VERSION ""

NS_ :

BS_:

BU_: XXX

BO_ 85 CID_TVHRJD: 8 XXX
 SG_ sig_fqiilo : 40|1@1+ (1,0) [0|1] "" XXX
 SG_ sig_sexmym : 56|8@1+ (1,0) [0|255] "" XXX

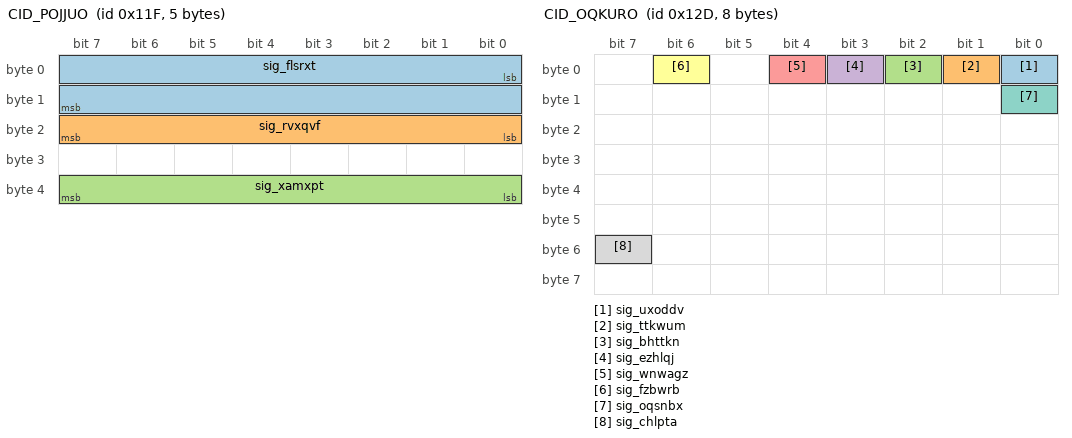
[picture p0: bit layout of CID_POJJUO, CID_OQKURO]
BO_ 287 CID_POJJUO: 5 XXX
 SG_ sig_flsrxt : 0|16@1- (0.1,0) [-450|450] "" XXX
 SG_ sig_rvxqvf : 16|8@1+ (4,0) [0|1020] "" XXX
 SG_ sig_xamxpt : 32|8@1+ (1,0) [0|255] "" XXX

BO_ 289 CID_ADYSGF: 8 XXX
 SG_ sig_qlnbtm : 0|12@1+ (1,0) [0|255] "" XXX

BO_ 301 CID_OQKURO: 8 XXX
 SG_ sig_uxoddv : 0|1@0+ (1,0) [0|1] "" XXX
 SG_ sig_ttkwum : 1|1@0+ (1,0) [0|1] "" XXX
 SG_ sig_bhttkn : 2|1@0+ (1,0) [0|1] "" XXX
 SG_ sig_ezhlqj : 3|1@0+ (1,0) [0|1] "" XXX
 SG_ sig_wnwagz : 4|1@0+ (1,0) [0|1] "" XXX
 SG_ sig_fzbwrb : 6|1@0+ (1,0) [0|1] "" XXX
 SG_ sig_oqsnbx : 8|1@0+ (1,0) [0|1] "" XXX
 SG_ sig_chlpta : 55|1@0+ (1,0) [0|1] "" XXX

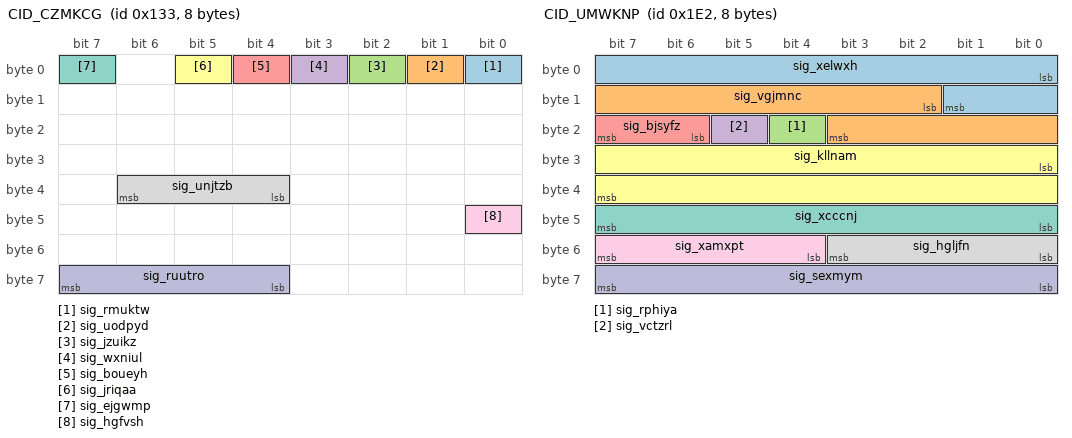
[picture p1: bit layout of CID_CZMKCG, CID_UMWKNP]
BO_ 307 CID_CZMKCG: 8 XXX
 SG_ sig_rmuktw : 0|1@0+ (1,0) [0|1] "" XXX
 SG_ sig_uodpyd : 1|1@1+ (1,0) [0|1] "" XXX
 SG_ sig_jzuikz : 2|1@1+ (1,0) [0|1] "" XXX
 SG_ sig_wxniul : 3|1@1+ (1,0) [0|1] "" XXX
 SG_ sig_boueyh : 4|1@0+ (1,0) [0|1] "" XXX
 SG_ sig_jriqaa : 5|1@0+ (1,0) [0|1] "" XXX
 SG_ sig_ejgwmp : 7|1@0+ (1,0) [0|1] "" XXX
 SG_ sig_unjtzb : 36|3@1+ (1,0) [0|7] "" XXX
 SG_ sig_hgfvsh : 40|1@0+ (1,0) [0|1] "" XXX
 SG_ sig_ruutro : 63|4@0+ (1,0) [0|15] "" XXX

BO_ 482 CID_UMWKNP: 8 XXX
 SG_ sig_xelwxh : 0|10@1- (0.01,0) [0|5] "" XXX
 SG_ sig_vgjmnc : 10|10@1- (0.01,0) [-5|0] "" XXX
 SG_ sig_rphiya : 20|1@0+ (1,0) [0|1] "" XXX
 SG_ sig_vctzrl : 21|1@0+ (1,0) [0|1] "" XXX
 SG_ sig_bjsyfz : 22|2@1+ (1,0) [0|1] "" XXX
 SG_ sig_kllnam : 24|16@1- (0.1,0) [-780|779.9] "" XXX
 SG_ sig_xcccnj : 47|8@0+ (1,0) [0|255] "" XXX
 SG_ sig_hgljfn : 48|4@1+ (1,0) [0|15] "" XXX
 SG_ sig_xamxpt : 52|4@1+ (1,0) [0|15] "" XXX
 SG_ sig_sexmym : 56|8@1+ (1,0) [0|255] "" XXX

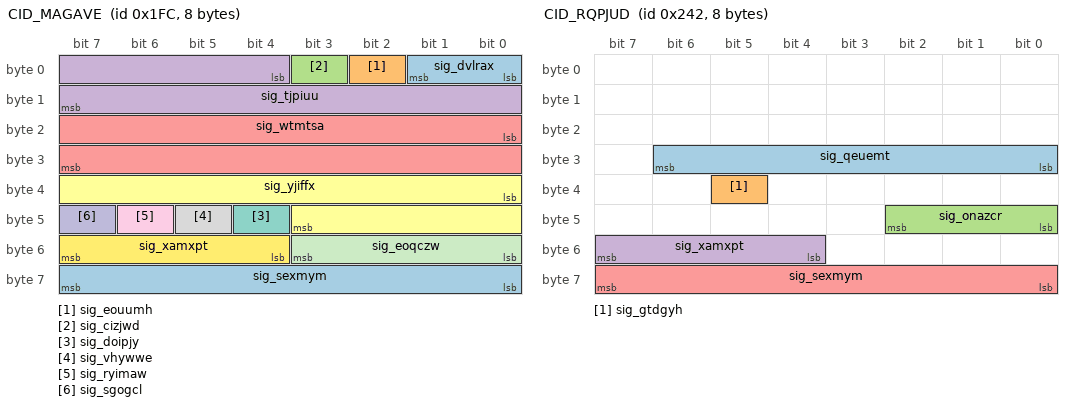
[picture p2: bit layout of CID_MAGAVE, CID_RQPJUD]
BO_ 508 CID_MAGAVE: 8 XXX
 SG_ sig_dvlrax : 0|2@1+ (1,0) [0|1] "" XXX
 SG_ sig_eouumh : 2|1@1+ (1,0) [0|1] "" XXX
 SG_ sig_cizjwd : 3|1@0+ (1,0) [0|1] "" XXX
 SG_ sig_tjpiuu : 4|12@1- (1,0) [-2048|2047] "" XXX
 SG_ sig_wtmtsa : 16|16@1- (0.1,0) [-780|779.9] "Deg" XXX
 SG_ sig_yjiffx : 32|12@1- (0.01,0) [0|63] "" XXX
 SG_ sig_doipjy : 44|1@0+ (1,0) [0|1] "" XXX
 SG_ sig_vhywwe : 45|1@1+ (1,0) [0|255] "" XXX
 SG_ sig_ryimaw : 46|1@1+ (1,0) [0|1] "" XXX
 SG_ sig_sgogcl : 47|1@0+ (1,0) [0|3] "" XXX
 SG_ sig_eoqczw : 48|4@1+ (1,0) [0|15] "" XXX
 SG_ sig_xamxpt : 52|4@1+ (1,0) [0|15] "" XXX
 SG_ sig_sexmym : 56|8@1+ (1,0) [0|255] "" XXX

BO_ 578 CID_RQPJUD: 8 XXX
 SG_ sig_qeuemt : 30|7@0+ (1,0) [0|127] "" XXX
 SG_ sig_gtdgyh : 37|1@0+ (1,0) [0|1] "" XXX
 SG_ sig_onazcr : 40|3@1+ (1,0) [0|7] "" XXX
 SG_ sig_xamxpt : 55|4@0+ (1,0) [0|15] "" XXX
 SG_ sig_sexmym : 56|8@1+ (1,0) [0|255] "" XXX

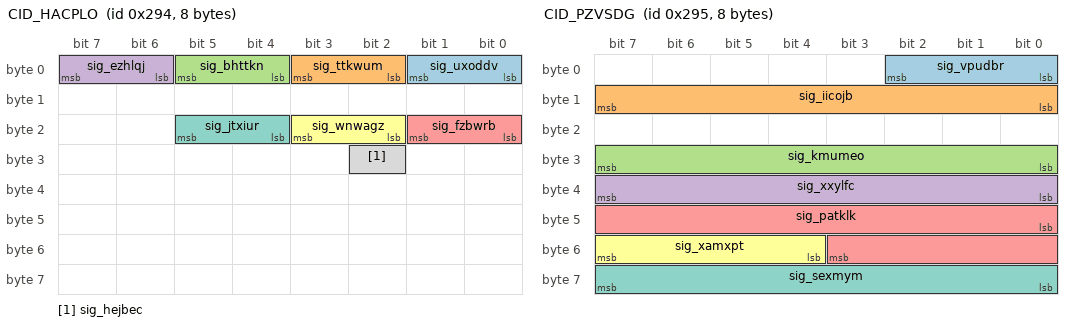
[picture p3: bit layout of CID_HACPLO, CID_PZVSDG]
BO_ 660 CID_HACPLO: 8 XXX
 SG_ sig_uxoddv : 1|2@0+ (1,0) [0|3] "" XXX
 SG_ sig_ttkwum : 3|2@0+ (1,0) [0|3] "" XXX
 SG_ sig_bhttkn : 5|2@0+ (1,0) [0|3] "" XXX
 SG_ sig_ezhlqj : 7|2@0+ (1,0) [0|3] "" XXX
 SG_ sig_fzbwrb : 17|2@0+ (1,0) [0|3] "" XXX
 SG_ sig_wnwagz : 19|2@0+ (1,0) [0|3] "" XXX
 SG_ sig_jtxiur : 21|2@0+ (1,0) [0|3] "" XXX
 SG_ sig_hejbec : 26|1@0+ (1,0) [0|1] "" XXX

BO_ 661 CID_PZVSDG: 8 XXX
 SG_ sig_vpudbr : 2|3@0+ (1,0) [0|7] "" XXX
 SG_ sig_iicojb : 15|8@0+ (1,0) [0|255] "" XXX
 SG_ sig_kmumeo : 31|8@0+ (1,0) [0|255] "" XXX
 SG_ sig_xxylfc : 32|8@1+ (1,0) [0|255] "" XXX
 SG_ sig_patklk : 40|12@1+ (1,0) [0|255] "" XXX
 SG_ sig_xamxpt : 52|4@1+ (1,0) [0|15] "" XXX
 SG_ sig_sexmym : 63|8@0+ (1,0) [0|255] "" XXX

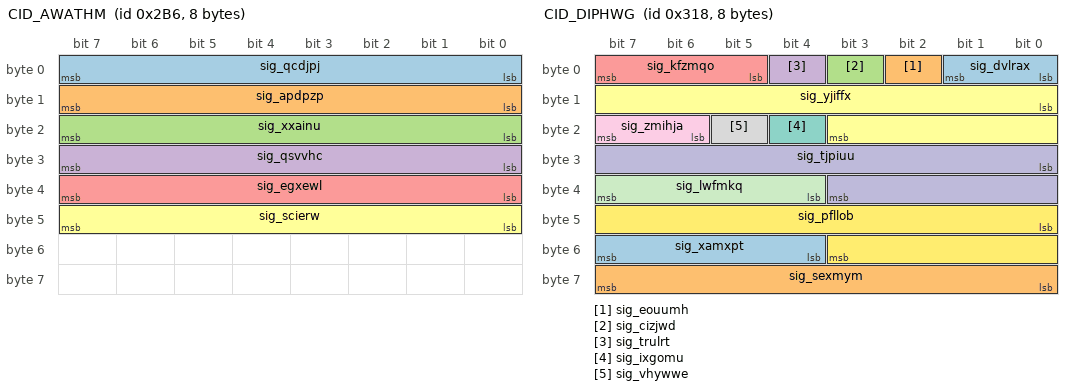
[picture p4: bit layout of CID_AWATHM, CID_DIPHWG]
BO_ 694 CID_AWATHM: 8 XXX
 SG_ sig_qcdjpj : 7|8@0+ (1,0) [0|255] "" XXX
 SG_ sig_apdpzp : 15|8@0+ (1,0) [0|255] "" XXX
 SG_ sig_xxainu : 23|8@0+ (1,0) [0|255] "" XXX
 SG_ sig_qsvvhc : 31|8@0+ (1,0) [0|255] "" XXX
 SG_ sig_egxewl : 39|8@0+ (1,0) [0|255] "" XXX
 SG_ sig_scierw : 47|8@0+ (1,0) [0|255] "" XXX

BO_ 790 CID_NQWMXH: 8 XXX
 SG_ sig_nwiqqp : 3|4@0+ (1,0) [0|1] "" XXX
 SG_ sig_dndjfb : 4|2@1+ (1,0) [0|3] "" XXX
 SG_ sig_wgoupi : 6|2@1+ (1,0) [0|3] "" XXX
 SG_ sig_kgfmkr : 8|2@1+ (1,0) [0|3] "" XXX
 SG_ sig_uyyupf : 10|1@1+ (1,0) [0|1] "" XXX
 SG_ sig_xxpklw : 11|4@1+ (1,0) [0|1] "" XXX
 SG_ sig_njyilw : 15|1@0+ (1,0) [0|1] "" XXX
 SG_ sig_kllnam : 16|11@1- (1,0) [-1024|1023] "" XXX
 SG_ sig_rphiya : 27|1@1+ (1,0) [0|1] "" XXX
 SG_ sig_vctzrl : 28|1@1+ (1,0) [0|3] "" XXX
 SG_ sig_sdakms : 29|1@0+ (1,0) [0|1] "" XXX
 SG_ sig_wikmzh : 30|1@0+ (1,0) [0|1] "" XXX
 SG_ sig_yrdwur : 31|1@0+ (1,0) [0|1] "" XXX
 SG_ sig_iaizdm : 32|2@1+ (1,0) [0|3] "" XXX
 SG_ sig_emhjmk : 34|2@1+ (1,0) [0|3] "" XXX
 SG_ sig_ukcrdt : 36|4@1+ (1,0) [0|3] "" XXX
 SG_ sig_ysjhoc : 40|8@1+ (5,-5) [-5|1270] "" XXX
 SG_ sig_knonlj : 49|2@0+ (1,0) [0|3] "" XXX
 SG_ sig_fgedvk : 51|2@0+ (1,0) [0|3] "" XXX
 SG_ sig_xamxpt : 52|4@1+ (1,0) [0|15] "" XXX
 SG_ sig_sexmym : 56|8@1+ (1,0) [0|15] "" XXX

BO_ 792 CID_DIPHWG: 8 XXX
 SG_ sig_dvlrax : 0|2@1+ (1,0) [0|1] "" XXX
 SG_ sig_eouumh : 2|1@1+ (1,0) [0|1] "" XXX
 SG_ sig_cizjwd : 3|1@1+ (1,0) [0|1] "" XXX
 SG_ sig_trulrt : 4|1@1+ (1,0) [0|1] "" XXX
 SG_ sig_kfzmqo : 5|3@1+ (1,0) [0|1] "" XXX
 SG_ sig_yjiffx : 8|12@1- (1,0) [-2048|2047] "" XXX
 SG_ sig_ixgomu : 20|1@1+ (1,0) [0|1] "" XXX
 SG_ sig_vhywwe : 21|1@1+ (1,0) [0|1] "" XXX
 SG_ sig_zmihja : 22|2@1+ (1,0) [0|15] "" XXX
 SG_ sig_tjpiuu : 24|12@1- (1,0) [-2048|2047] "" XXX
 SG_ sig_lwfmkq : 36|4@1+ (1,0) [0|15] "" XXX
 SG_ sig_pfllob : 40|12@1+ (1,0) [0|4095] "" XXX
 SG_ sig_xamxpt : 52|4@1+ (1,0) [0|15] "" XXX
 SG_ sig_sexmym : 56|8@1+ (1,0) [0|255] "" XXX

BO_ 813 CID_GNLPUX: 8 XXX
 SG_ sig_ppxeiv : 0|9@1+ (0.5,0) [0|255.5] "" XXX
 SG_ sig_kmrues : 9|1@1+ (1,0) [0|1] "" XXX
 SG_ sig_lvkuim : 10|3@1+ (1,0) [0|7] "" XXX
 SG_ sig_qpysdm : 13|3@1+ (1,0) [0|7] "" XXX
 SG_ sig_fuhzkz : 16|1@1+ (1,0) [0|1] "" XXX
 SG_ sig_tnttmr : 17|1@1+ (1,0) [0|1] "" XXX
 SG_ sig_cizjwd : 18|1@1+ (1,0) [0|1] "" XXX
 SG_ sig_fzukmv : 19|3@1+ (1,0) [0|1] "" XXX
 SG_ sig_rkdffw : 22|1@0+ (1,0) [0|1] "" XXX
 SG_ sig_xjtniy : 23|1@0+ (1,0) [0|1] "" XXX
 SG_ sig_kgfmkr : 24|1@1+ (1,0) [0|1] "" XXX
 SG_ sig_ckxebz : 25|7@1+ (1,0) [0|127] "" XXX
 SG_ sig_vuawwu : 32|4@1+ (1,0) [0|15] "" XXX
 SG_ sig_mmwewd : 36|12@1+ (1,0) [0|4095] "" XXX
 SG_ sig_xamxpt : 48|4@1+ (1,0) [0|15] "" XXX
 SG_ sig_yztuax : 55|4@0+ (1,0) [0|15] "" XXX
 SG_ sig_sexmym : 56|8@1+ (1,0) [0|255] "" XXX

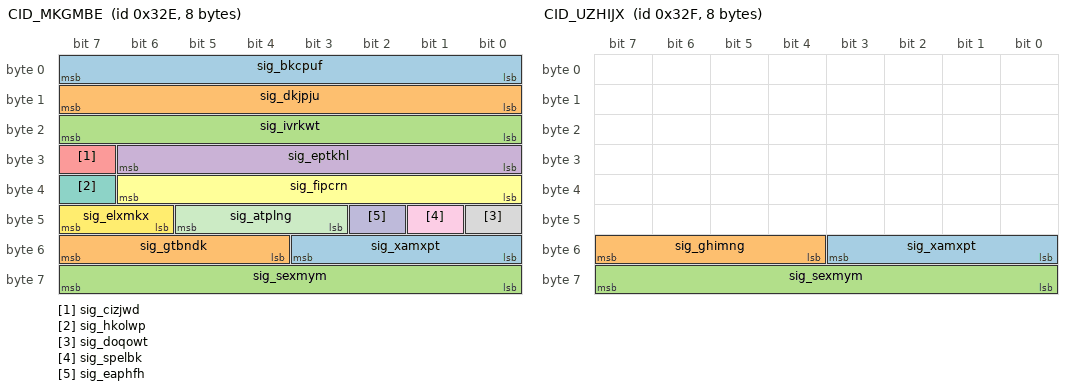
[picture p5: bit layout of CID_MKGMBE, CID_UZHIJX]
BO_ 814 CID_MKGMBE: 8 XXX
 SG_ sig_bkcpuf : 0|8@1+ (0.05,-5) [-100|155] "" XXX
 SG_ sig_dkjpju : 8|8@1+ (0.05,-5) [0|1.26] "" XXX
 SG_ sig_ivrkwt : 16|8@1+ (0.05,-5) [0|1.26] "" XXX
 SG_ sig_eptkhl : 24|7@1+ (0.2,0) [0|12.7] "" XXX
 SG_ sig_cizjwd : 31|1@0+ (1,0) [0|1] "" XXX
 SG_ sig_fipcrn : 32|7@1+ (0.2,-16) [0|12.7] "" XXX
 SG_ sig_hkolwp : 39|1@0+ (1,0) [0|1] "" XXX
 SG_ sig_doqowt : 40|1@0+ (1,0) [0|1] "" XXX
 SG_ sig_spelbk : 41|1@0+ (1,0) [0|1] "" XXX
 SG_ sig_eaphfh : 42|1@1+ (1,0) [0|3] "" XXX
 SG_ sig_atplng : 45|3@0+ (1,0) [0|1] "" XXX
 SG_ sig_elxmkx : 46|2@1+ (1,0) [0|3] "" XXX
 SG_ sig_xamxpt : 48|4@1+ (1,0) [0|15] "" XXX
 SG_ sig_gtbndk : 55|4@0+ (1,0) [0|15] "" XXX
 SG_ sig_sexmym : 56|8@1+ (1,0) [0|255] "" XXX

BO_ 815 CID_UZHIJX: 8 XXX
 SG_ sig_xamxpt : 48|4@1+ (1,0) [0|15] "" XXX
 SG_ sig_ghimng : 55|4@0+ (1,0) [0|15] "" XXX
 SG_ sig_sexmym : 56|8@1+ (1,0) [0|255] "" XXX

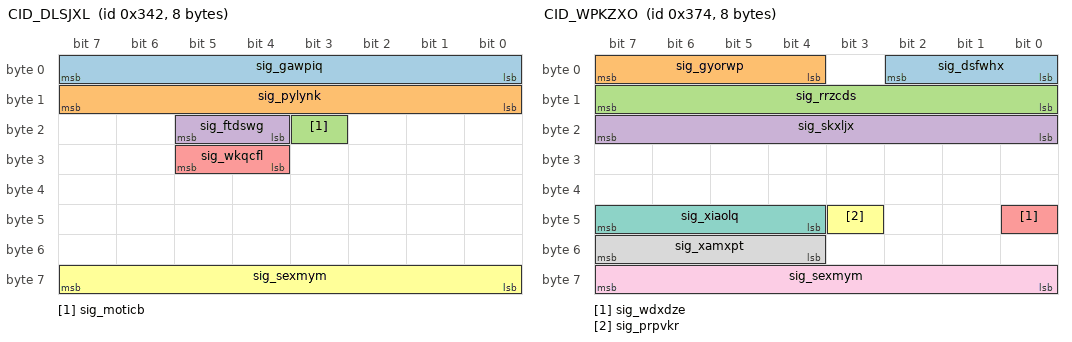
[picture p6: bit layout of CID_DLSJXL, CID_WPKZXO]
BO_ 834 CID_DLSJXL: 8 XXX
 SG_ sig_gawpiq : 0|8@1+ (0.01,0) [0|2.55] "" XXX
 SG_ sig_pylynk : 8|8@1+ (0.01,0) [0|2.55] "" XXX
 SG_ sig_moticb : 19|1@1+ (1,0) [0|1] "" XXX
 SG_ sig_ftdswg : 20|2@1+ (1,0) [0|255] "" XXX
 SG_ sig_wkqcfl : 28|2@1+ (1,0) [0|1] "" XXX
 SG_ sig_sexmym : 56|8@1+ (1,0) [0|255] "" XXX

 BO_ 884 CID_WPKZXO: 8 MRR
 SG_ sig_dsfwhx : 2|3@0+ (1,0) [0|3] "" MRR
 SG_ sig_gyorwp : 7|4@0+ (1,0) [0|15] "" MRR
 SG_ sig_rrzcds : 15|8@0+ (0.1,-12) [0|255] "" MRR
 SG_ sig_skxljx : 23|8@0+ (1,-100) [0|255] "" MRR
 SG_ sig_wdxdze : 40|1@0+ (1,0) [0|3] "" MRR
 SG_ sig_prpvkr : 43|1@0+ (1,0) [0|1] "" XXX
 SG_ sig_xiaolq : 44|4@1+ (1,0) [0|15] "" XXX
 SG_ sig_xamxpt : 52|4@1+ (1,0) [0|15] "" MRR
 SG_ sig_sexmym : 56|8@1+ (1,0) [0|255] "" MRR

BO_ 944 CID_UTZKFK: 8 XXX
 SG_ sig_uxpikb : 1|2@0+ (1,0) [0|3] "" XXX
 SG_ sig_qeswhu : 2|1@0+ (1,0) [0|1] "" XXX
 SG_ sig_qwzmfa : 4|2@0+ (1,0) [0|3] "" XXX
 SG_ sig_wbwnrm : 5|1@0+ (1,0) [0|1] "" XXX
 SG_ sig_jviexk : 6|1@0+ (1,0) [0|1] "" XXX
 SG_ sig_akayle : 7|1@0+ (1,0) [0|1] "" XXX
 SG_ sig_gkprcl : 8|1@0+ (1,0) [0|1] "" XXX
 SG_ sig_pwghkc : 11|3@0+ (1,0) [0|7] "" XXX
 SG_ sig_ogaobm : 12|1@0+ (1,0) [0|1] "" XXX
 SG_ sig_ccuyxp : 14|2@0+ (1,0) [0|3] "" XXX
 SG_ sig_pvaegn : 15|1@0+ (1,0) [0|1] "" XXX
 SG_ sig_zjkmzb : 16|1@0+ (1,0) [0|1] "" XXX
 SG_ sig_fjyjvr : 18|2@0+ (1,0) [0|3] "" XXX
 SG_ sig_ddjgyu : 19|1@0+ (1,0) [0|1] "" XXX
 SG_ sig_vqfzcn : 23|4@0+ (1,0) [0|15] "" XXX
 SG_ sig_kofktk : 24|28@1+ (1,0) [0|268435455] "" XXX
 SG_ sig_xamxpt : 52|4@1+ (1,0) [0|15] "" XXX
 SG_ sig_sexmym : 56|8@1+ (1,0) [0|255] "" XXX

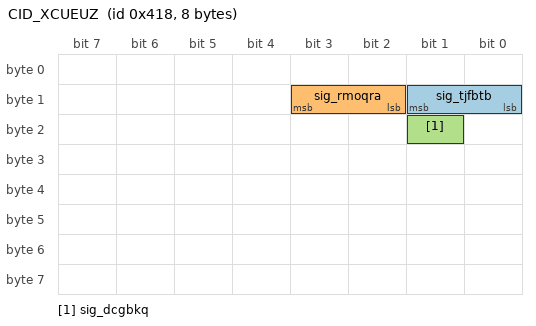
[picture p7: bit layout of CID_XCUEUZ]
BO_ 1048 CID_XCUEUZ: 8 XXX
 SG_ sig_tjfbtb : 9|2@0+ (1,0) [0|1] "" XXX
 SG_ sig_rmoqra : 11|2@0+ (1,0) [0|1] "" XXX
 SG_ sig_dcgbkq : 17|1@0+ (1,0) [0|1] "" XXX

VAL_ 578 sig_onazcr 4 "D" 2 "R" 3 "N" 1 "P";
VAL_ 790 sig_nwiqqp 11 "AutoFullBeamActive" 2 "AutoFullBeamInactive";
VAL_ 790 sig_dndjfb 0 "GRAY" 1 "GREEN" 2 "YELLOW" 3 "RED";
VAL_ 790 sig_wgoupi 3 "ALARM_AND_LKA" 2 "LKA" 1 "ALARM" 0 "DISABLE";
VAL_ 790 sig_emhjmk 0 "GRAY" 1 "GREEN" 2 "YELLOW" 3 "RED";
VAL_ 790 sig_knonlj 0 "VIBRATION" 1 "AUDIO" 2 "AUDIO_AND_VIBRATION";
VAL_ 792 sig_dvlrax 0 "NotReady" 1 "Ready" 2 "Active" 3 "TemporaryFail";
VAL_ 813 sig_lvkuim 4 "4BAR" 3 "3BAR" 2 "2BAR" 1 "1BAR";
VAL_ 813 sig_fzukmv 0 "OFF" 2 "ACC_ON" 3 "ACC_ACTIVE" 5 "FORCE_ACCEL" 7 "ERROR";
VAL_ 813 sig_ckxebz 36 "ACC_ERROR" 22 "OVERRIDE" 12 "ENGAGE" 8 "DISENGAGE" 20 "ACC_ON" 32 "ACC_OFF" 48 "CHECK_GEAR_D" 16 "FORCE_ACCEL" 0 "NONE";
VAL_ 814 sig_atplng 0 "Off" 1 "Passive" 2 "StandBy" 3 "ActiveControl" 4 "BrakeOnly" 5 "Override" 6 "Standstill" 7 "Failure";
VAL_ 814 sig_elxmkx 0 "Softoff" 1 "Fastoff" 2 "Immediateoff" 3 "Initial";
VAL_ 834 sig_ftdswg 2 "SPORT" 1 "ECO" 0 "SNOW";
VAL_ 834 sig_wkqcfl 3 "HEV" 2 "FORCE_EV" 1 "EV";
VAL_ 944 sig_qwzmfa 0 "NOTPRESSED" 1 "DOWN_SETSPEED" 3 "UP_RESETSPEED";
